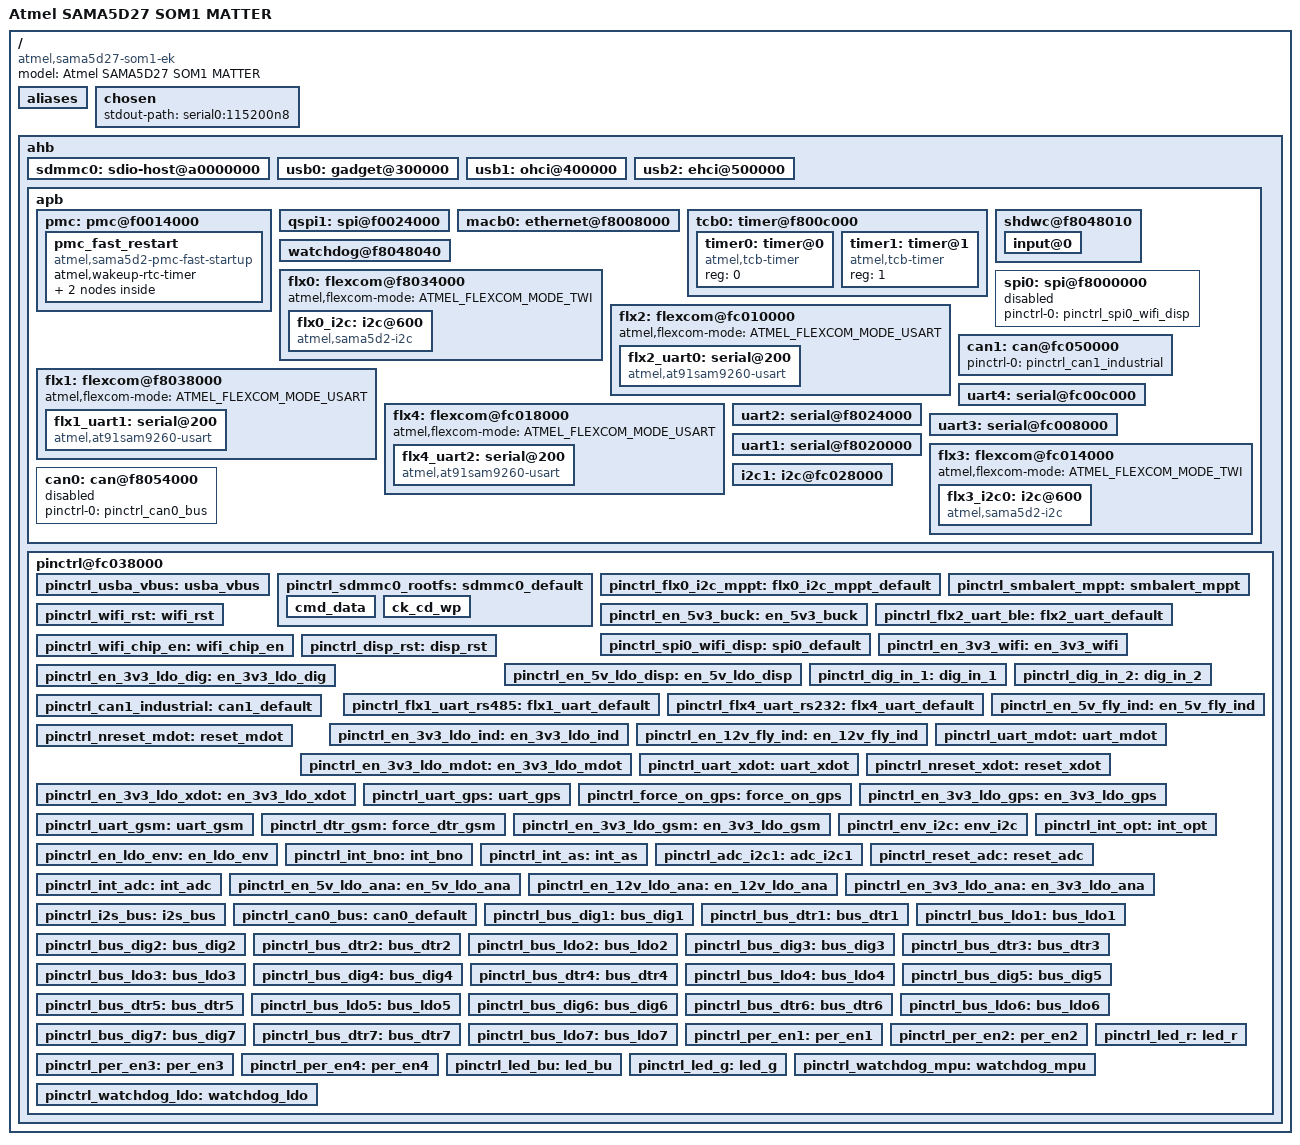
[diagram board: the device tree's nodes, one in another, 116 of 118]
// SPDX-License-Identifier: (GPL-2.0+ OR MIT)
/*
 * at91-sama5d27_som1_matter.dts - Device Tree file for SAMA5D27-SOM1-MATTER board
 *
 *
 *
 *
 *
 */
/dts-v1/;
#include "at91-sama5d27_som1.dtsi"
#include <dt-bindings/mfd/atmel-flexcom.h>
#include <dt-bindings/gpio/gpio.h>

/ {
	model = "Atmel SAMA5D27 SOM1 MATTER";
	compatible = "atmel,sama5d27-som1-ek", "atmel,sama5d27-som1", "atmel,sama5d27", "atmel,sama5d2", "atmel,sama5", "atmel,sama5d27-som1-matter";

	aliases 
	{
		sd0		= &sdmmc0;		/* root fs */
		USBDebug	= &usb0;    		/* Debug USB micro */ 
		flx0_i2c_mppt	= &flx0_i2c;		/* MPPT I2C */
		flx2_uart_ble 	= &flx2_uart0; 		/* UART BLE */
		spi_wifi_disp	= &spi0;    		/* Wifi and Disp SPI */
		flx1_uart_rs485 = &flx1_uart1;   	/* UART RS485 */
		flx4_uart_rs232 = &flx4_uart2;   	/* UART RS232 */
		uart4_mdot	= &uart4;		/* UART MDOT */
		uart2_xdot	= &uart2;		/* UART XDOT */
		uart3_gps	= &uart3;		/* UART GPS */
		uart1_gps	= &uart1;		/* UART GSM */
		flx3_i2c_env	= &flx3_i2c0;       	/* I2C ENVIRONMENTALS */
		i2c_adc		= &i2c1;		/* I2C ADC */
		
	};

	chosen 
	{
		stdout-path = "serial0:115200n8";
	};

	ahb 
	{
		//SD CARD
		sdmmc0: sdio-host@a0000000 
		{
			bus-width = <4>;
			pinctrl-names = "default";
			pinctrl-0 = <&pinctrl_sdmmc0_rootfs>;
			status = "okay";
		};
		//USB DEBUGGING		
		usb0: gadget@300000 
		{
			atmel,vbus-gpio = <&pioA PIN_PD20 GPIO_ACTIVE_HIGH>;
			pinctrl-names = "default";
			pinctrl-0 = <&pinctrl_usba_vbus>;
			status = "okay";
		};
		//USB TO HUB
		usb1: ohci@400000 
		{
			status = "okay";
		};

		usb2: ehci@500000 {
			status = "okay";
		};

		apb 
		{
		//POWER MANAGEMENT?
			pmc: pmc@f0014000 
			{
				pmc_fast_restart 
				{
					compatible = "atmel,sama5d2-pmc-fast-startup";
					#address-cells = <1>;
					#size-cells = <0>;

					atmel,wakeup-rtc-timer;

					wkpin: input@0 
					{
						reg = <0>;
					};

					gmac_wol: input@10 
					{
						reg = <10>;
						atmel,wakeup-active-high;
					};
				};
			};

			qspi1: spi@f0024000 
			{
				status = "okay";
			};
			//ETHERNET
			macb0: ethernet@f8008000 
			{
				status = "okay";
			};

			tcb0: timer@f800c000 
			{
				timer0: timer@0 
				{
					compatible = "atmel,tcb-timer";
					reg = <0>;
				};

				timer1: timer@1 
				{
					compatible = "atmel,tcb-timer";
					reg = <1>;
				};
			};
			//SHUTDOWN?	
			shdwc@f8048010 
			{
				atmel,shdwc-debouncer = <976>;
				atmel,wakeup-rtc-timer;

				input@0 
				{
					reg = <0>;
					atmel,wakeup-type = "low";
				};
			};
			//INTERNAL WATCHDOG?
			watchdog@f8048040 
			{
				status = "okay";
			};
			//MPPT/POWER I2C FLEXCOM0
			flx0: flexcom@f8034000
			{
				atmel,flexcom-mode = <ATMEL_FLEXCOM_MODE_TWI>;
				status = "okay";

				flx0_i2c: i2c@600 
				{
					compatible = "atmel,sama5d2-i2c";
					reg = <0x600 0x200>;
					interrupts = <19 IRQ_TYPE_LEVEL_HIGH 7>;
					dmas = <0>, <0>;
					dma-names = "tx", "rx";
					#address-cells = <1>;
					#size-cells = <0>;
					clocks = <&flx0_clk>;
					pinctrl-names = "default";
					pinctrl-0 = <&pinctrl_flx0_i2c_mppt>;
					atmel,fifo-size = <16>;
					status = "okay";
				};
			};	
			//BLE UART FLEXCOM2			
			flx2: flexcom@fc010000 
			{ 
				atmel,flexcom-mode = <ATMEL_FLEXCOM_MODE_USART>;
				status = "okay";

				flx2_uart0: serial@200 
				{
					compatible = "atmel,at91sam9260-usart";
					reg = <0x200 0x200>;
					interrupts = <21 IRQ_TYPE_LEVEL_HIGH 7>;
					clocks = <&flx2_clk>;
					clock-names = "usart";
					pinctrl-names = "default";
					pinctrl-0 = <&pinctrl_flx2_uart_ble>;
					atmel,fifo-size = <32>;
					status = "okay"; //Dedicated to BLE, No conflicts
				};
			};
			//WIFI/DISPLAY SPI				
			spi0: spi@f8000000 
			{
				pinctrl-names = "default";
				pinctrl-0 = <&pinctrl_spi0_wifi_disp>;
				status = "disabled";
			};  //GPIOs for control specified only in pin control section
			//RS485 FLEXCOM1 UART
			flx1: flexcom@f8038000 
			{
				atmel,flexcom-mode = <ATMEL_FLEXCOM_MODE_USART>;
				status = "okay";

				flx1_uart1: serial@200 
				{
					compatible = "atmel,at91sam9260-usart";
					reg = <0x200 0x200>;
					interrupts = <20 IRQ_TYPE_LEVEL_HIGH 7>;
					clocks = <&flx1_clk>;
					clock-names = "usart";
					pinctrl-names = "default";
					pinctrl-0 = <&pinctrl_flx1_uart_rs485>;
					atmel,fifo-size = <32>;
					status = "okay"; //Dedicated to RS485, No conflicts
				};
			};
			//RS232 FLEXCOM4 UART			
			flx4: flexcom@fc018000 
			{
				atmel,flexcom-mode = <ATMEL_FLEXCOM_MODE_USART>;
				status = "okay";

				flx4_uart2: serial@200 
				{
					compatible = "atmel,at91sam9260-usart";
					reg = <0x200 0x200>;
					interrupts = <23 IRQ_TYPE_LEVEL_HIGH 7>;
					clocks = <&flx4_clk>;
					clock-names = "usart";
					pinctrl-names = "default";
					pinctrl-0 = <&pinctrl_flx4_uart_rs232>;
					atmel,fifo-size = <32>;
					status = "okay"; //Dedicated to RS232, No Conflicts
				};
			};
			//CAN BUS INDUSTRIAL COMMS			
			can1: can@fc050000 
			{ //Check this node, may need to move up one level!
				pinctrl-names = "default";
				pinctrl-0 = <&pinctrl_can1_industrial>;
				status = "okay";
			};
			//MDOT UART
			uart4: serial@fc00c000 
			{
				atmel,use-dma-rx;
				atmel,use-dma-tx;
				pinctrl-names = "default";
				pinctrl-0 = <&pinctrl_uart_mdot>;
				status = "okay";
			};
			//XDOT UART
			uart2: serial@f8024000 
			{
				atmel,use-dma-rx;
				atmel,use-dma-tx;
				pinctrl-names = "default";
				pinctrl-0 = <&pinctrl_uart_xdot>;
				status = "okay";
			};
			//GPS UART			
			uart3: serial@fc008000 
			{
				atmel,use-dma-rx;
				atmel,use-dma-tx;
				pinctrl-names = "default";
				pinctrl-0 = <&pinctrl_uart_gps>;
				status = "okay";
			};
			//GSM UART			
			uart1: serial@f8020000 
			{
				atmel,use-dma-rx;
				atmel,use-dma-tx;
				pinctrl-names = "default";
				pinctrl-0 = <&pinctrl_uart_gsm>;
				status = "okay";
			};
			//ENVIRONMENTALS/BUS FLEXCOM3 I2C
			flx3: flexcom@fc014000 
			{
				atmel,flexcom-mode = <ATMEL_FLEXCOM_MODE_TWI>;
				status = "okay";
				
				flx3_i2c0: i2c@600 
				{
					compatible = "atmel,sama5d2-i2c";
					reg = <0x600 0x200>;
					interrupts = <22 IRQ_TYPE_LEVEL_HIGH 7>;
					dmas = <0>, <0>;
					dma-names = "tx", "rx";
					#address-cells = <1>;
					#size-cells = <0>;
					clocks = <&flx3_clk>;
					pinctrl-names = "default";
					pinctrl-0 = <&pinctrl_env_i2c>;
					atmel,fifo-size = <16>;
					status = "okay";
				};
			};
			//ADC I2C1
			i2c1: i2c@fc028000 
			{
				dmas = <0>, <0>;
				pinctrl-names = "default";
				pinctrl-0 = <&pinctrl_adc_i2c1>;
				status = "okay";
			};


			//BUS I2S
			//RESEARCH
			//BUS CAN0   
			can0: can@f8054000
			{ //Check this node, may need to move up one level!
				pinctrl-names = "default";
				pinctrl-0 = <&pinctrl_can0_bus>;
				status = "disabled";
			};
		};
/*___________________________________________Pin Control________________________________________________*/

			pinctrl@fc038000 
			{
			//DEFAULTS UNCHANGED
			//USB DETECT
				pinctrl_usba_vbus: usba_vbus 
				{
					pinmux = <PIN_PD20__GPIO>;
					bias-disable;
				};				
				//SD Card rootfs		
				pinctrl_sdmmc0_rootfs: sdmmc0_default 
				{
						cmd_data 
						{
							pinmux = <PIN_PA1__SDMMC0_CMD>,
									 <PIN_PA2__SDMMC0_DAT0>,
									 <PIN_PA3__SDMMC0_DAT1>,
									 <PIN_PA4__SDMMC0_DAT2>,
									 <PIN_PA5__SDMMC0_DAT3>;
							bias-disable;
						};
						ck_cd_wp 
						{
							pinmux = <PIN_PA0__SDMMC0_CK>,
								   //<PIN_PA11__SDMMC0_VDDSEL>, //Removed
									 <PIN_PA12__SDMMC0_WP>, //Added
									 <PIN_PA13__SDMMC0_CD>;
							bias-disable;
						};
					};
				//MPPT/POWER I2C					
				pinctrl_flx0_i2c_mppt: flx0_i2c_mppt_default 
				{
					pinmux = <PIN_PB28__FLEXCOM0_IO0>,
						 <PIN_PB29__FLEXCOM0_IO1>;
					bias-disable;
				};
				//MPPT/POWER CONTROL
				pinctrl_smbalert_mppt: smbalert_mppt 
				{
					pinmux = <PIN_PA31__GPIO>;
					bias-disable;
				};
				pinctrl_en_5v3_buck: en_5v3_buck 
				{
					pinmux = <PIN_PA30__GPIO>;
					bias-disable;
				};				
				//BLE UART
				pinctrl_flx2_uart_ble: flx2_uart_default 
				{
					pinmux = <PIN_PA6__FLEXCOM2_IO0>,
						 <PIN_PA7__FLEXCOM2_IO1>,
						 <PIN_PA9__FLEXCOM2_IO3>,
						 <PIN_PA10__FLEXCOM2_IO4>;
					bias-disable;
				};
				//WIFI/DISPLAY SPI				
				pinctrl_spi0_wifi_disp: spi0_default 
				{
					pinmux = <PIN_PA14__SPI0_SPCK>,
						 <PIN_PA15__SPI0_MOSI>,
						 <PIN_PA16__SPI0_MISO>,
						 <PIN_PA17__SPI0_NPCS0>, //Wifi CS
						 <PIN_PA18__SPI0_NPCS1>; //Disp CS
					bias-disable;
				};
				//WIFI CONTROL
				pinctrl_en_3v3_wifi: en_3v3_wifi 
				{
					pinmux = <PIN_PA28__GPIO>;
					bias-disable;
				};
						
				pinctrl_wifi_rst: wifi_rst 
				{
					pinmux = <PIN_PD1__GPIO>;
					bias-disable;
				};
						
				pinctrl_wifi_chip_en: wifi_chip_en 
				{
					pinmux = <PIN_PD25__GPIO>;
					bias-disable;
				};
				//DISPLAY CONTROL						
				pinctrl_disp_rst: disp_rst 
				{
					pinmux = <PIN_PA26__GPIO>;
					bias-disable;
				};
						
				pinctrl_en_5v_ldo_disp: en_5v_ldo_disp 
				{
					pinmux = <PIN_PC15__GPIO>;
					bias-disable;
				};
				//DIGITAL INPUTS AND CONTROL
				pinctrl_dig_in_1: dig_in_1 
				{
					pinmux = <PIN_PA20__GPIO>;
					bias-disable;
				};
						
				pinctrl_dig_in_2: dig_in_2 
				{
					pinmux = <PIN_PA21__GPIO>;
					bias-disable;
				};
				
				pinctrl_en_3v3_ldo_dig: en_3v3_ldo_dig 
				{
					pinmux = <PIN_PA22__GPIO>;
					bias-disable;
				};

				//RS485 UART
				pinctrl_flx1_uart_rs485: flx1_uart_default 
				{
					pinmux = <PIN_PA23__FLEXCOM1_IO1>,
						 <PIN_PA24__FLEXCOM1_IO0>,
						 <PIN_PA25__FLEXCOM1_IO3>,
						 <PIN_PA26__FLEXCOM1_IO4>;
					bias-disable;
				};
				//RS232 UART				
				pinctrl_flx4_uart_rs232: flx4_uart_default 
				{
					pinmux = <PIN_PC28__FLEXCOM4_IO0>,
						 <PIN_PC29__FLEXCOM4_IO1>,
						 <PIN_PC31__FLEXCOM4_IO3>,
						 <PIN_PD0__FLEXCOM4_IO4>;
					bias-disable;
				};
				//CAN BUS INDUSTRIAL						
				pinctrl_can1_industrial: can1_default 
				{
					pinmux = <PIN_PC26__CANTX1>,
						 <PIN_PC27__CANRX1>;
					bias-disable;
				};
				//INDUSTRIAL COMMS POWER CONTROL					
				pinctrl_en_3v3_ldo_ind: en_3v3_ldo_ind 
				{
					pinmux = <PIN_PA11__GPIO>;
					bias-disable;
				};
				
				pinctrl_en_5v_fly_ind: en_5v_fly_ind 
				{
					pinmux = <PIN_PA19__GPIO>;
					bias-disable;
				};
				
				pinctrl_en_12v_fly_ind: en_12v_fly_ind 
				{
					pinmux = <PIN_PA27__GPIO>;
					bias-disable;
				};
				//MDOT UART
				pinctrl_uart_mdot: uart_mdot 
				{
					pinmux = <PIN_PB3__URXD4>,
						 <PIN_PB4__UTXD4>;
					bias-disable;
				};
				//MDOT CONTROL
				pinctrl_nreset_mdot: reset_mdot 
				{
					pinmux = <PIN_PB1__GPIO>;
					bias-disable;
				};
				
				pinctrl_en_3v3_ldo_mdot: en_3v3_ldo_mdot 
				{
					pinmux = <PIN_PB2__GPIO>;
					bias-disable;
				};
				//XDOT UART
				pinctrl_uart_xdot: uart_xdot 
				{
					pinmux = <PIN_PD23__URXD2>,
						 <PIN_PD24__UTXD2>;
					bias-disable;
				};
				//XDOT CONTROL
				pinctrl_nreset_xdot: reset_xdot 
				{
					pinmux = <PIN_PC19__GPIO>;
					bias-disable;
				};
				
				pinctrl_en_3v3_ldo_xdot: en_3v3_ldo_xdot 
				{
					pinmux = <PIN_PC30__GPIO>;
					bias-disable;
				};
				//GPS UART
				pinctrl_uart_gps: uart_gps 
				{
					pinmux = <PIN_PC12__URXD3>,
						 <PIN_PC13__UTXD3>;
					bias-disable;
				};
				//GPS CONTROL
				pinctrl_force_on_gps: force_on_gps 
				{
					pinmux = <PIN_PC9__GPIO>;
					bias-disable;
				};
				
				pinctrl_en_3v3_ldo_gps: en_3v3_ldo_gps 
				{
					pinmux = <PIN_PC17__GPIO>;
					bias-disable;
				};
				//GSM UART
				pinctrl_uart_gsm: uart_gsm 
				{
					pinmux = <PIN_PD2__URXD1>,
						 <PIN_PD3__UTXD1>;
					bias-disable;
				};
				//GSM CONTROL
				pinctrl_dtr_gsm: force_dtr_gsm 
				{
					pinmux = <PIN_PD22__GPIO>;
					bias-disable;
				};
				
				pinctrl_en_3v3_ldo_gsm: en_3v3_ldo_gsm 
				{
					pinmux = <PIN_PC21__GPIO>;
					bias-disable;
				};
				//ENVIRONMENTALS I2C				
				pinctrl_env_i2c: env_i2c 
				{
					pinmux = <PIN_PB23__FLEXCOM3_IO0>,
						 <PIN_PB22__FLEXCOM3_IO1>;
					bias-disable;
				};
				//ENVIRONMENTALS CONTROL				
				pinctrl_en_ldo_env: en_ldo_env 
				{
					pinmux = <PIN_PC20__GPIO>;
					bias-disable;
				};	

				pinctrl_int_opt: int_opt 
				{
					pinmux = <PIN_PA8__GPIO>;
					bias-disable;
				};

				pinctrl_int_bno: int_bno 
				{
					pinmux = <PIN_PC10__GPIO>;
					bias-disable;
				};	

				pinctrl_int_as: int_as 
				{
					pinmux = <PIN_PC22__GPIO>;
					bias-disable;
				};					
				//ADC I2C1				
				pinctrl_adc_i2c1: adc_i2c1 
				{
					pinmux = <PIN_PD4__TWD1>,
						 <PIN_PD5__TWCK1>;
					bias-disable;
				};
				//ADC CONTROL
				pinctrl_reset_adc: reset_adc 
				{
					pinmux = <PIN_PD6__GPIO>;
					bias-disable;
				};	

				pinctrl_int_adc: int_adc 
				{
					pinmux = <PIN_PD7__GPIO>;
					bias-disable;
				};

				pinctrl_en_5v_ldo_ana: en_5v_ldo_ana 
				{
					pinmux = <PIN_PD8__GPIO>;
					bias-disable;
				};	

				pinctrl_en_12v_ldo_ana: en_12v_ldo_ana 
				{
					pinmux = <PIN_PD21__GPIO>;
					bias-disable;
				};

				pinctrl_en_3v3_ldo_ana: en_3v3_ldo_ana 
				{
					pinmux = <PIN_PD26__GPIO>;
					bias-disable;
				};
				//BUS I2S		
				pinctrl_i2s_bus: i2s_bus 
				{
					pinmux = <PIN_PB14__I2SC1_MCK>,
						 <PIN_PB15__I2SC1_CK>,
						 <PIN_PB16__I2SC1_WS>,
						 <PIN_PB17__I2SC1_DI0>,
						 <PIN_PB18__I2SC1_DO0>;
					bias-disable;
				};	
				//BUS CAN BUS
				pinctrl_can0_bus: can0_default 
				{
					pinmux = <PIN_PC1__CANTX0>,
						 <PIN_PC2__CANRX0>;
					bias-disable;
				};				
				//BUS CONTROL
				//CHANNEL 1
				pinctrl_bus_dig1: bus_dig1 
				{
					pinmux = <PIN_PB5__GPIO>;
					bias-disable;
				};		
				pinctrl_bus_dtr1: bus_dtr1 
				{
					pinmux = <PIN_PB7__GPIO>;
					bias-disable;
				};
				pinctrl_bus_ldo1: bus_ldo1 
				{
					pinmux = <PIN_PB9__GPIO>;
					bias-disable;
				};
				//CHANNEL 2
				pinctrl_bus_dig2: bus_dig2 
				{
					pinmux = <PIN_PC5__GPIO>;
					bias-disable;
				};		
				pinctrl_bus_dtr2: bus_dtr2 
				{
					pinmux = <PIN_PC4__GPIO>;
					bias-disable;
				};
				pinctrl_bus_ldo2: bus_ldo2 
				{
					pinmux = <PIN_PB10__GPIO>;
					bias-disable;
				};
				//CHANNEL 3
				pinctrl_bus_dig3: bus_dig3 
				{
					pinmux = <PIN_PC6__GPIO>;
					bias-disable;
				};		
				pinctrl_bus_dtr3: bus_dtr3 
				{
					pinmux = <PIN_PC7__GPIO>;
					bias-disable;
				};
				pinctrl_bus_ldo3: bus_ldo3 
				{
					pinmux = <PIN_PC8__GPIO>;
					bias-disable;
				};
				//CHANNEL 4
				pinctrl_bus_dig4: bus_dig4 
				{
					pinmux = <PIN_PC0__GPIO>;
					bias-disable;
				};		
				pinctrl_bus_dtr4: bus_dtr4 
				{
					pinmux = <PIN_PB31__GPIO>;
					bias-disable;
				};
				pinctrl_bus_ldo4: bus_ldo4 
				{
					pinmux = <PIN_PC3__GPIO>;
					bias-disable;
				};
				//CHANNEL 5
				pinctrl_bus_dig5: bus_dig5 
				{
					pinmux = <PIN_PB13__GPIO>;
					bias-disable;
				};		
				pinctrl_bus_dtr5: bus_dtr5 
				{
					pinmux = <PIN_PB12__GPIO>;
					bias-disable;
				};
				pinctrl_bus_ldo5: bus_ldo5 
				{
					pinmux = <PIN_PB11__GPIO>;
					bias-disable;
				};
				//CHANNEL 6
				pinctrl_bus_dig6: bus_dig6 
				{
					pinmux = <PIN_PB25__GPIO>;
					bias-disable;
				};		
				pinctrl_bus_dtr6: bus_dtr6 
				{
					pinmux = <PIN_PB19__GPIO>;
					bias-disable;
				};
				pinctrl_bus_ldo6: bus_ldo6 
				{
					pinmux = <PIN_PB20__GPIO>;
					bias-disable;
				};
				//CHANNEL 7
				pinctrl_bus_dig7: bus_dig7 
				{
					pinmux = <PIN_PB30__GPIO>;
					bias-disable;
				};		
				pinctrl_bus_dtr7: bus_dtr7 
				{
					pinmux = <PIN_PB21__GPIO>;
					bias-disable;
				};
				pinctrl_bus_ldo7: bus_ldo7 
				{
					pinmux = <PIN_PB27__GPIO>;
					bias-disable;
				};
				//BUS PERIPHERAL CONTROL
				pinctrl_per_en1: per_en1 
				{
					pinmux = <PIN_PC18__GPIO>;
					bias-disable;
				};
				pinctrl_per_en2: per_en2 
				{
					pinmux = <PIN_PC25__GPIO>;
					bias-disable;
				};
				pinctrl_per_en3: per_en3 
				{
					pinmux = <PIN_PC16__GPIO>;
					bias-disable;
				};
				pinctrl_per_en4: per_en4 
				{
					pinmux = <PIN_PC11__GPIO>;
					bias-disable;
				};
				//LEDs
				pinctrl_led_r: led_r 
				{
					pinmux = <PIN_PB24__GPIO>;
					bias-disable;
				};
				pinctrl_led_bu: led_bu 
				{
					pinmux = <PIN_PB26__GPIO>;
					bias-disable;
				};
				pinctrl_led_g: led_g 
				{
					pinmux = <PIN_PC23__GPIO>;
					bias-disable;
				};
				//EXTERNAL WATCHDOG TIMERS
				pinctrl_watchdog_mpu: watchdog_mpu 
				{
					pinmux = <PIN_PD19__GPIO>;
					bias-disable;
				};
				pinctrl_watchdog_ldo: watchdog_ldo 
				{
					pinmux = <PIN_PC24__GPIO>;
					bias-disable;
				};
				
				
/*				pinctrl_led_gpio_default: led_gpio_default 
				{
					pinmux = <PIN_PA10__GPIO>,
						 <PIN_PB1__GPIO>,
						 <PIN_PA31__GPIO>;
					bias-pull-up;
				};*/	
			};			
		};
};
